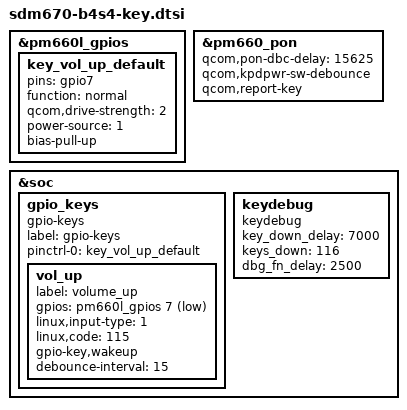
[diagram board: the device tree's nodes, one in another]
/* Copyright (c) 2018, The Linux Foundation. All rights reserved.
 *
 * This program is free software; you can redistribute it and/or modify
 * it under the terms of the GNU General Public License version 2 and
 * only version 2 as published by the Free Software Foundation.
 *
 * This program is distributed in the hope that it will be useful,
 * but WITHOUT ANY WARRANTY; without even the implied warranty of
 * MERCHANTABILITY or FITNESS FOR A PARTICULAR PURPOSE. See the
 * GNU General Public License for more details.
 */

&pm660l_gpios {
	key_vol_up_default: key_vol_up_default {
		pins = "gpio7";
		function = "normal";
		qcom,drive-strength = <2>;
		power-source = <1>;
		bias-pull-up;
	};
};

&pm660_pon {
	qcom,pon-dbc-delay = <15625>;
	qcom,kpdpwr-sw-debounce;
	qcom,report-key;
};

&soc {
	gpio_keys {
		compatible = "gpio-keys";
		label = "gpio-keys";
		status = "okay";
		pinctrl-names = "default";
		pinctrl-0 = <&key_vol_up_default>;

		vol_up {
			label = "volume_up";
			gpios = <&pm660l_gpios 7 GPIO_ACTIVE_LOW>;
			linux,input-type = <1>;
			linux,code = <115>;
			gpio-key,wakeup;
			debounce-interval = <15>;
		};
	};

	keydebug {
		compatible = "keydebug";
		key_down_delay = <7000>;
		keys_down = <116>;
		dbg_fn_delay = <2500>;
	};
};
